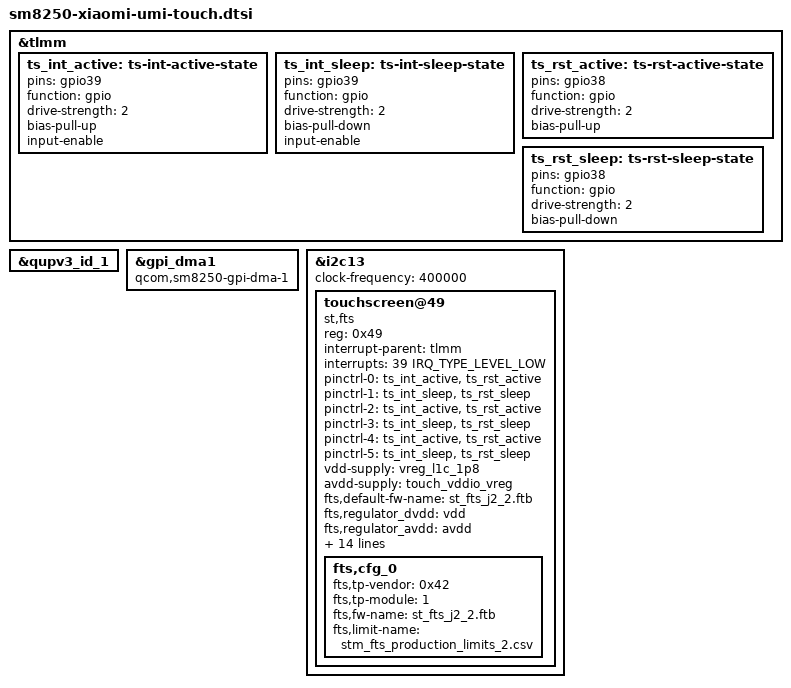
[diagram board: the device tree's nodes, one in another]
// SPDX-License-Identifier: BSD-3-Clause
/*
 * Xiaomi Mi 10 (umi) - STMicroelectronics "FTS" touchscreen
 *
 * This is the configuration that is verified working on this hardware (the
 * Armbian sm8250-xiaomi-umi port): the controller sits on GENI SE5
 * (i2c@a94000 == &i2c13) at 400 kHz, with the two bus pads muxed to the
 * "qup13" function exactly as the vendor stack leaves them.
 *
 * History: this used to be bit-banged from the driver because the SE has its
 * FIFO interface disabled (GENI_IF_DISABLE_RO) so mainline geni-i2c has to go
 * through GPI DMA, and GPI never answered EV ALLOCATE:
 *
 *     gpi a00000.dma-controller: cmd: EV ALLOCATE completion timeout:2
 *     geni_i2c a94000.i2c: error -ENODEV: Failed to setup GPI DMA mode
 *
 * A working tree on the same SoC proves the controller can be used, so this
 * file now just enables the standard QUP path.  patches/umi-i2c.c (the
 * bit-bang adapter) is still in the tree; it simply has no device node any
 * more, so nothing binds to it.
 *
 * The three pins the driver still owns:
 *   - reset : GPIO38, active high (out of reset)
 *             vendor: fts,reset-gpio = <&tlmm 0x26 0x00>
 *   - irq   : GPIO39, level low
 *             vendor: fts,irq-gpio = <&tlmm 0x27 0x2008>
 *
 * Supply mapping, re-verified against the vendor DT (dump/downstream.dts,
 * fts@49) and against the running kernel:
 *
 *   vdd  (bus / IO, 1.8 V) -> vreg_l1c_1p8
 *       = RPMH resource LDOc1.  The vendor DT calls the very same resource
 *       pm8150a_l1 (aliases L1C = ".../rpmh-regulator-ldoc1/regulator-
 *       pm8150a-l1"); mainline simply labels pmic-id "c" as PM8150L.  At
 *       runtime the consumer shows up as "13-0049-vdd" on vreg_l1c_1p8.
 *   avdd (power, 3.3 V)    -> touch_vddio_vreg  (GPIO69 gated rail)
 *       = the vendor's disp_vddio_vreg (gpio = <&tlmm 0x45>), shared with
 *       the display flex.  The vendor driver sets it to 3300000 uV.
 *
 * The vendor power-up order is enable(vdd) -> set_voltage(avdd) ->
 * enable(avdd); fts_power_on() in fts521/fts.c does exactly that.
 */

#include <dt-bindings/gpio/gpio.h>
#include <dt-bindings/interrupt-controller/irq.h>

/* --- pin states ---------------------------------------------------------- */

/*
 * No bus pin state here on purpose: gpio36/gpio37 belong to the QUP now and
 * are described by qup_i2c13_default in sm8250.dtsi (function "qup13").
 * Claiming them with function "gpio" would put them back into the GPIO block
 * and the controller would no longer drive them.
 */
&tlmm {
	/* The vendor parks the interrupt line with a pull-down while the chip is
	 * asleep, so it cannot float high and keep the GIC armed. */
	ts_int_active: ts-int-active-state {
		pins = "gpio39";
		function = "gpio";
		drive-strength = <2>;
		bias-pull-up;
		input-enable;
	};

	ts_int_sleep: ts-int-sleep-state {
		pins = "gpio39";
		function = "gpio";
		drive-strength = <2>;
		bias-pull-down;
		input-enable;
	};

	/*
	 * Reset is driven through gpiod (fts,reset-gpio / reset-gpios), so the
	 * pin state only has to put the pad into GPIO mode - no output-* here,
	 * that would fight the descriptor.
	 */
	ts_rst_active: ts-rst-active-state {
		pins = "gpio38";
		function = "gpio";
		drive-strength = <2>;
		bias-pull-up;
	};

	ts_rst_sleep: ts-rst-sleep-state {
		pins = "gpio38";
		function = "gpio";
		drive-strength = <2>;
		bias-pull-down;
	};
};

/* --- the QUP stack ------------------------------------------------------- */

&qupv3_id_1 {
	status = "okay";
};

/*
 * gpi_dma1 needs a non-zero EE register offset.
 *
 * sm8250 has two GPI DMA controllers whose EE registers do not sit at the
 * start of their register windows.  Newer mainline names the two variants
 * "qcom,sm8250-gpi-dma-0" (ee_offset 0x1000) and "qcom,sm8250-gpi-dma-1"
 * (ee_offset 0x6000); this tree (6.12.94) only carries the single
 * "qcom,sm8250-gpi-dma", whose match data is ee_offset 0.  With that offset
 * the driver computes a wrong ee_base for wrap1 and every GPI command goes
 * unanswered:
 *
 *     gpi a00000.dma-controller: cmd: EV ALLOCATE completion timeout:2
 *     gpi a00000.dma-controller: error alloc_ev_chan:-5
 *     geni_i2c a94000.i2c: error -ENODEV: Failed to setup GPI DMA mode
 *
 * The two match entries are added by scripts/build.sh, which patches
 * drivers/dma/qcom/gpi.c in the kernel tree before building.
 */
&gpi_dma1 {
	compatible = "qcom,sm8250-gpi-dma-1", "qcom,sdm845-gpi-dma";
	status = "okay";
};

/* --- the bus and the controller ----------------------------------------- */

&i2c13 {
	status = "okay";
	clock-frequency = <400000>;

	touchscreen@49 {
		compatible = "st,fts";
		reg = <0x49>;

		interrupt-parent = <&tlmm>;
		interrupts = <39 IRQ_TYPE_LEVEL_LOW>;

		/*
		 * Name the states after what the drivers actually look up.
		 *
		 * fts521/fts.h redefines the kernel's state names:
		 *
		 *     #define PINCTRL_STATE_ACTIVE  "default"
		 *     #define PINCTRL_STATE_SUSPEND "sleep"
		 *
		 * so fts521/fts.c looks up "default" and "sleep" (not
		 * "active"/"suspend").  The "default" lookup is a dev_err and
		 * used to print "Can not lookup default pinstate -19"; the
		 * "sleep" one is a dev_dbg, so it failed silently and only
		 * "[ FTS ] fts_probe: Failed to init pinctrl" was left behind.
		 *
		 * pinctrl_bind_pins() in drivers/base/pinctrl.c also wants a
		 * "default" state.  The vendor (Xiaomi) driver spelling
		 * "pmx_ts_active"/"pmx_ts_suspend" is kept as well.
		 */
		pinctrl-names = "default", "sleep",
				"active", "suspend",
				"pmx_ts_active", "pmx_ts_suspend";
		pinctrl-0 = <&ts_int_active &ts_rst_active>;	/* default */
		pinctrl-1 = <&ts_int_sleep &ts_rst_sleep>;	/* sleep */
		pinctrl-2 = <&ts_int_active &ts_rst_active>;
		pinctrl-3 = <&ts_int_sleep &ts_rst_sleep>;
		pinctrl-4 = <&ts_int_active &ts_rst_active>;
		pinctrl-5 = <&ts_int_sleep &ts_rst_sleep>;

		/*
		 * Supply mapping taken from MIUI, not from the other working DTS.
		 *
		 * On a running MIUI the regulator state is:
		 *   vreg_l1c_1p8     1800 mV  consumer 4900000003.touchscreen-vdd
		 *   touch_vddio_vreg 3300 mV  1 user
		 * so vdd (bus) is the 1.8 V PM8150L LDO and avdd (power) is the
		 * GPIO69 gated rail.  That also matches the vendor driver, which
		 * programs avdd with regulator_set_voltage(avdd, 3300000, 3300000).
		 *
		 * The other working tree has these two swapped; with avdd on the
		 * fixed 1.8 V rail that call fails and every raw sample comes back
		 * identical (-13462), i.e. the analogue front end never sees a
		 * valid acquisition.
		 */
		vdd-supply = <&vreg_l1c_1p8>;
		avdd-supply = <&touch_vddio_vreg>;
		/*
		 * 同一份 DT 要同时伺候两个驱动：
		 *   fts521（主线移植版，默认）只认 regulator_* / default-fw-name
		 *   stfts （厂商 5.2.4，TOUCH=stfts 时用）认 pwr/bus-reg-name 和
		 *          config-array（它按 lockdown 的 tp-vendor 选 FW/limits）
		 * 多出来的属性对另一边是无害的，所以不拆两份 DT。
		 *
		 * tp-vendor 0x42 / module 1 = 本机 lockdown（53 42 32 01 74 02 32 01）。
		 */
		fts,default-fw-name = "st_fts_j2_2.ftb";
		fts,regulator_dvdd = "vdd";
		fts,regulator_avdd = "avdd";

		fts,pwr-reg-name = "avdd";
		fts,bus-reg-name = "vdd";
		fts,config-array-size = <1>;

		fts,irq-gpio = <&tlmm 39 GPIO_ACTIVE_LOW>;
		fts,irq-gpio-name = "fts_irq";
		fts,reset-gpio-enable;
		/*
		 * 两套属性并存：
		 *   fts,reset-gpio  6.12 的驱动自己解析（vendor 命名）
		 *   reset-gpios     7.x 的驱动用 devm_gpiod_get(dev, "reset") 取
		 */
		fts,reset-gpio = <&tlmm 38 GPIO_ACTIVE_HIGH>;
		reset-gpios = <&tlmm 38 GPIO_ACTIVE_HIGH>;
		fts,reset-gpio-name = "fts_rst";
		/*
		 * 厂商 stfts 驱动把这个值直接喂给 request_threaded_irq(…, NULL,
		 * handler, flags, …)。主线程为 NULL 时**必须带 IRQF_ONESHOT**，
		 * 否则内核返回 -EINVAL，驱动只打一句 "Request irq failed" 就整个
		 * probe 失败。厂商 DT 用的是 0x2008 = IRQF_ONESHOT |
		 * IRQF_TRIGGER_LOW，照抄。
		 *（fts521 不看这个属性，改了对它没影响。）
		 */
		fts,irq-flags = <0x2008>;	/* IRQF_ONESHOT | IRQF_TRIGGER_LOW */

		fts,x-max = <1080>;
		fts,y-max = <2340>;

		touchscreen-size-x = <1080>;
		touchscreen-size-y = <2340>;

		status = "okay";

		/*
		 * 厂商 stfts 驱动按 lockdown 的 tp-vendor 选 FW/limits。
		 * 本机 lockdown = 53 42 32 01 74 02 32 01 → tp-vendor 0x42, module 1。
		 * 子节点必须放在所有属性之后（dtc 要求 properties precede subnodes）。
		 */
		fts,cfg_0 {
			fts,tp-vendor = <0x42>;
			fts,tp-module = <1>;
			fts,fw-name = "st_fts_j2_2.ftb";
			fts,limit-name = "stm_fts_production_limits_2.csv";
		};
	};
};

/*
 * No regulator-always-on on vreg_l1c_1p8 any more.
 *
 * The old note claimed this rail is the vendor's pm8150a_l1 and that mainline
 * cannot drive it, so it had to be pinned on.  That was wrong twice over: it
 * IS the same RPMH resource (LDOc1), and the vendor driver enables it itself
 * (consumer "13-0049-vdd").  Pinning it always-on only kept the touch rail
 * powered across suspend, where fts_power_off() does disable it on purpose.
 */
